AUTOSAR XML (schema 4.0)
package /Powertrain_Components
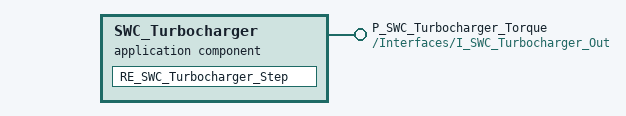
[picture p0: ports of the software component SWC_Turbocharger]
  application sw component type SWC_Turbocharger  # AUTOSAR Application SWC SWC_Turbocharger for Powertrain Control
    provide port P_SWC_Turbocharger_Torque: provided-interface=/Interfaces/I_SWC_Turbocharger_Out
    behavior SWC_Turbocharger_Behavior
      runnable RE_SWC_Turbocharger_Step: symbol=SWC_Turbocharger_Step
  sender receiver interface I_SWC_Turbocharger_Out
    data DE_SWC_Turbocharger_TorqueDemand: type=/AUTOSAR/Platform/uint32
